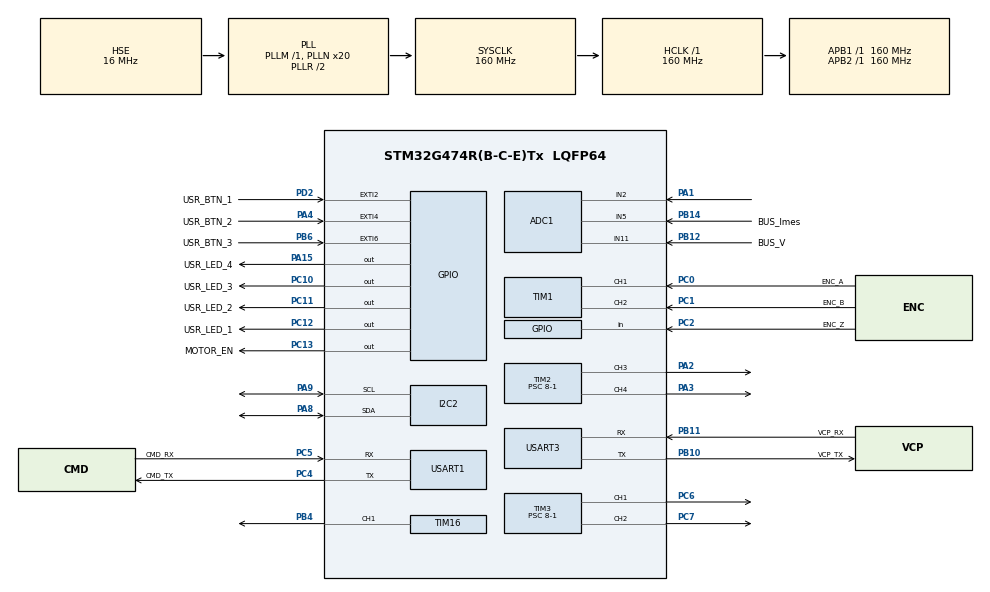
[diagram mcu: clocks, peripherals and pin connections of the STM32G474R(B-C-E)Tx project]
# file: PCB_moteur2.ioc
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ADC1.Channel-0\#ChannelRegularConversion=ADC_CHANNEL_5
ADC1.NbrOfConversionFlag=1
ADC1.OffsetNumber-0\#ChannelRegularConversion=ADC_OFFSET_NONE
ADC1.Rank-0\#ChannelRegularConversion=1
ADC1.SamplingTime-0\#ChannelRegularConversion=ADC_SAMPLETIME_2CYCLES_5
ADC1.master=1
I2C2.Timing=0x30D29DE4
Mcu.Family=STM32G4
Mcu.Name=STM32G474R(B-C-E)Tx
Mcu.Package=LQFP64
NVIC.PriorityGroup=NVIC_PRIORITYGROUP_4
PA1.Mode=IN2-Single-Ended
PA1.Signal=ADC1_IN2
PA13.Mode=Trace_Asynchronous_SW
PA13.Signal=SYS_JTMS-SWDIO
PA14.Mode=Trace_Asynchronous_SW
PA14.Signal=SYS_JTCK-SWCLK
PA15.GPIO_Label=USR_LED_4
PA15.Signal=GPIO_Output
PA2.Signal=S_TIM2_CH3
PA3.Signal=S_TIM2_CH4
PA4.GPIO_Label=USR_BTN_2
PA4.Signal=GPXTI4
PA8.Mode=I2C
PA8.Signal=I2C2_SDA
PA9.Mode=I2C
PA9.Signal=I2C2_SCL
PB10.GPIO_Label=VCP_TX
PB10.Mode=Asynchronous
PB10.Signal=USART3_TX
PB11.GPIO_Label=VCP_RX
PB11.Mode=Asynchronous
PB11.Signal=USART3_RX
PB12.GPIO_Label=BUS_V
PB12.Mode=IN11-Single-Ended
PB12.Signal=ADC1_IN11
PB14.GPIO_Label=BUS_Imes
PB14.Mode=IN5-Single-Ended
PB14.Signal=ADC1_IN5
PB3.Mode=Trace_Asynchronous_SW
PB3.Signal=SYS_JTDO-SWO
PB4.Signal=S_TIM16_CH1
PB6.GPIO_Label=USR_BTN_3
PB6.Signal=GPXTI6
PC0.GPIO_Label=ENC_A
PC0.Signal=S_TIM1_CH1
PC1.GPIO_Label=ENC_B
PC1.Signal=S_TIM1_CH2
PC10.GPIO_Label=USR_LED_3
PC10.Signal=GPIO_Output
PC11.GPIO_Label=USR_LED_2
PC11.Signal=GPIO_Output
PC12.GPIO_Label=USR_LED_1
PC12.Signal=GPIO_Output
PC13.GPIO_Label=MOTOR_EN
PC13.Signal=GPIO_Output
PC2.GPIO_Label=ENC_Z
PC2.Signal=GPIO_Input
PC4.GPIO_Label=CMD_TX
PC4.Mode=Asynchronous
PC4.Signal=USART1_TX
PC5.GPIO_Label=CMD_RX
PC5.Mode=Asynchronous
PC5.Signal=USART1_RX
PC6.Signal=S_TIM3_CH1
PC7.Signal=S_TIM3_CH2
PD2.GPIO_Label=USR_BTN_1
PD2.Signal=GPXTI2
PF0-OSC_IN.Mode=HSE-External-Oscillator
PF0-OSC_IN.Signal=RCC_OSC_IN
PF1-OSC_OUT.Mode=HSE-External-Oscillator
PF1-OSC_OUT.Signal=RCC_OSC_OUT
ProjectManager.HeapSize=0x200
ProjectManager.StackSize=0x400
ProjectManager.TargetToolchain=STM32CubeIDE
RCC.ADC12Freq_Value=160000000
RCC.ADC345Freq_Value=160000000
RCC.AHBFreq_Value=160000000
RCC.APB1Freq_Value=160000000
RCC.APB1TimFreq_Value=160000000
RCC.APB2Freq_Value=160000000
RCC.APB2TimFreq_Value=160000000
RCC.CortexFreq_Value=160000000
RCC.EXTERNAL_CLOCK_VALUE=12288000
RCC.HCLKFreq_Value=160000000
RCC.HSE_VALUE=16000000
RCC.HSI48_VALUE=48000000
RCC.HSI_VALUE=16000000
RCC.LSE_VALUE=32768
RCC.PLLN=20
RCC.PLLSourceVirtual=RCC_PLLSOURCE_HSE
RCC.SYSCLKFreq_VALUE=160000000
RCC.SYSCLKSource=RCC_SYSCLKSOURCE_PLLCLK
RCC.USBFreq_Value=160000000
RCC.VCOOutputFreq_Value=320000000
SH.S_TIM16_CH1.0=TIM16_CH1,Output Compare1 CH1
SH.S_TIM1_CH1.0=TIM1_CH1,Encoder_Interface
SH.S_TIM1_CH2.0=TIM1_CH2,Encoder_Interface
SH.S_TIM2_CH3.0=TIM2_CH3,PWM Generation3 CH3
SH.S_TIM2_CH4.0=TIM2_CH4,PWM Generation4 CH4
SH.S_TIM3_CH1.0=TIM3_CH1,PWM Generation1 CH1
SH.S_TIM3_CH2.0=TIM3_CH2,PWM Generation2 CH2
TIM16.Channel=TIM_CHANNEL_1
TIM2.AutoReloadPreload=TIM_AUTORELOAD_PRELOAD_ENABLE
TIM2.Channel-PWM\ Generation3\ CH3=TIM_CHANNEL_3
TIM2.Channel-PWM\ Generation4\ CH4=TIM_CHANNEL_4
TIM2.CounterMode=TIM_COUNTERMODE_CENTERALIGNED1
TIM2.OCPolarity_4=TIM_OCPOLARITY_LOW
TIM2.PeriodNoDither=1000-1
TIM2.Prescaler=8-1
TIM2.PulseNoDither_3=600
TIM2.PulseNoDither_4=400
TIM2.TIM_MasterOutputTrigger=TIM_TRGO_UPDATE
TIM2.TIM_MasterSlaveMode=TIM_MASTERSLAVEMODE_ENABLE
TIM3.AutoReloadPreload=TIM_AUTORELOAD_PRELOAD_ENABLE
TIM3.Channel-PWM\ Generation1\ CH1=TIM_CHANNEL_1
TIM3.Channel-PWM\ Generation2\ CH2=TIM_CHANNEL_2
TIM3.CounterMode=TIM_COUNTERMODE_CENTERALIGNED1
TIM3.OCPolarity_2=TIM_OCPOLARITY_LOW
TIM3.PeriodNoDither=1000-1
TIM3.Prescaler=8-1
TIM3.PulseNoDither_1=400
TIM3.PulseNoDither_2=600
TIM3.TIM_MasterSlaveMode=TIM_MASTERSLAVEMODE_DISABLE
USART1.VirtualMode-Asynchronous=VM_ASYNC
USART3.VirtualMode-Asynchronous=VM_ASYNC
VP_SYS_VS_DBSignals.Mode=DisableDeadBatterySignals
VP_TIM16_VS_ClockSourceINT.Mode=Enable_Timer
VP_TIM2_VS_ClockSourceINT.Mode=Internal
VP_TIM3_VS_ClockSourceINT.Mode=Internal
VP_TIM3_VS_ClockSourceITR.Mode=TriggerSource_ITR1
VP_TIM3_VS_ControllerModeTrigger.Mode=Trigger Mode
board=custom

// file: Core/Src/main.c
/* USER CODE BEGIN Header */
/**
 ******************************************************************************
 * @file           : main.c
 * @brief          : Main program body
 ******************************************************************************
 * @attention
 *
 * Copyright (c) 2025 STMicroelectronics.
 * All rights reserved.
 *
 * This software is licensed under terms that can be found in the LICENSE file
 * in the root directory of this software component.
 * If no LICENSE file comes with this software, it is provided AS-IS.
 *
 ******************************************************************************
 */
/* USER CODE END Header */
#include "main.h"
#include "adc.h"
#include "i2c.h"
#include "tim.h"
#include "usart.h"
#include "gpio.h"

/* USER CODE BEGIN PV */
float alpha=0;
float V=0;
/* USER CODE END PV */

void SystemClock_Config(void);

int main(void)
{

	/* MCU Configuration--------------------------------------------------------*/

	/* Reset of all peripherals, Initializes the Flash interface and the Systick. */
	HAL_Init();

	/* Configure the system clock */
	SystemClock_Config();

	/* Initialize all configured peripherals */
	MX_GPIO_Init();
	MX_TIM2_Init();
	MX_TIM3_Init();
	MX_ADC1_Init();
	MX_I2C2_Init();
	MX_TIM1_Init();
	MX_TIM16_Init();
	MX_USART1_UART_Init();
	MX_USART3_UART_Init();
	/* USER CODE BEGIN 2 */
	//  HAL_TIM_PWM_Start(&htim2, TIM_CHANNEL_3); //PA2 TIM2 CH3 symétrique PC7
	//  HAL_TIM_PWM_Start(&htim3, TIM_CHANNEL_1); //PC6 TIM3 CH1
	//  HAL_TIM_PWM_Start(&htim2, TIM_CHANNEL_4);
	//  HAL_TIM_PWM_Start(&htim3, TIM_CHANNEL_2);
	HAL_TIM_PWM_Start(&htim2, TIM_CHANNEL_3);
	HAL_TIM_PWM_Start(&htim2, TIM_CHANNEL_4);
	HAL_TIM_PWM_Start(&htim3, TIM_CHANNEL_1);
	HAL_TIM_PWM_Start(&htim3, TIM_CHANNEL_2);
	//  HAL_TIM_PWM_Stop();
	/* USER CODE END 2 */

	/* Infinite loop */
	/* USER CODE BEGIN WHILE */
	while (1)
	{// freq 20 K, presc à 0, pres à 7, pi avec simulink, aller voir Mr Martin
		//	  V=24;
		//	  alpha=(V/24 +1)*(1/2);//  paramètre V a donné
		//	  __HAL_TIM_SET_COMPARE(&htim2, TIM_CHANNEL_3, 1000);
		//	  //__HAL_TIM_SET_COMPARE(&htim3, TIM_CHANNEL_1, 1000);
		//	  //__HAL_TIM_SET_COMPARE(&htim2, TIM_CHANNEL_4, 1000);
		//	  //__HAL_TIM_SET_COMPARE(&htim3, TIM_CHANNEL_2, 1000);
		//	  HAL_Delay(1000);
		//	  __HAL_TIM_SET_COMPARE(&htim2, TIM_CHANNEL_3, 0);
		//	  //__HAL_TIM_SET_COMPARE(&htim3, TIM_CHANNEL_1, 0);
		//	  //__HAL_TIM_SET_COMPARE(&htim2, TIM_CHANNEL_4, 0);
		//	  //__HAL_TIM_SET_COMPARE(&htim3, TIM_CHANNEL_2, 0);
		//	  HAL_Delay(1000);

		HAL_GPIO_TogglePin(USR_LED_1_GPIO_Port, USR_LED_1_Pin);
		HAL_GPIO_TogglePin(USR_LED_2_GPIO_Port, USR_LED_2_Pin);
		HAL_GPIO_TogglePin(USR_LED_3_GPIO_Port, USR_LED_3_Pin);
		HAL_GPIO_TogglePin(USR_LED_4_GPIO_Port, USR_LED_4_Pin);
		HAL_Delay(1000);
		/* USER CODE END WHILE */

	}
}

void SystemClock_Config(void)
{
	RCC_OscInitTypeDef RCC_OscInitStruct = {0};
	RCC_ClkInitTypeDef RCC_ClkInitStruct = {0};

	/** Configure the main internal regulator output voltage
	 */
	HAL_PWREx_ControlVoltageScaling(PWR_REGULATOR_VOLTAGE_SCALE1_BOOST);

	/** Initializes the RCC Oscillators according to the specified parameters
	 * in the RCC_OscInitTypeDef structure.
	 */
	RCC_OscInitStruct.OscillatorType = RCC_OSCILLATORTYPE_HSE;
	RCC_OscInitStruct.HSEState = RCC_HSE_ON;
	RCC_OscInitStruct.PLL.PLLState = RCC_PLL_ON;
	RCC_OscInitStruct.PLL.PLLSource = RCC_PLLSOURCE_HSE;
	RCC_OscInitStruct.PLL.PLLM = RCC_PLLM_DIV1;
	RCC_OscInitStruct.PLL.PLLN = 20;
	RCC_OscInitStruct.PLL.PLLP = RCC_PLLP_DIV2;
	RCC_OscInitStruct.PLL.PLLQ = RCC_PLLQ_DIV2;
	RCC_OscInitStruct.PLL.PLLR = RCC_PLLR_DIV2;
	if (HAL_RCC_OscConfig(&RCC_OscInitStruct) != HAL_OK)
	{
		Error_Handler();
	}

	/** Initializes the CPU, AHB and APB buses clocks
	 */
	RCC_ClkInitStruct.ClockType = RCC_CLOCKTYPE_HCLK|RCC_CLOCKTYPE_SYSCLK
			|RCC_CLOCKTYPE_PCLK1|RCC_CLOCKTYPE_PCLK2;
	RCC_ClkInitStruct.SYSCLKSource = RCC_SYSCLKSOURCE_PLLCLK;
	RCC_ClkInitStruct.AHBCLKDivider = RCC_SYSCLK_DIV1;
	RCC_ClkInitStruct.APB1CLKDivider = RCC_HCLK_DIV1;
	RCC_ClkInitStruct.APB2CLKDivider = RCC_HCLK_DIV1;

	if (HAL_RCC_ClockConfig(&RCC_ClkInitStruct, FLASH_LATENCY_4) != HAL_OK)
	{
		Error_Handler();
	}
}

void Error_Handler(void)
{
	__disable_irq();
	while (1)
	{
	}
}
